# pwrseq_me17 register map
Registers are access not given, no defined reset value unless marked. A register's access mark holds for its fields unless they carry their own. Offsets are from the block's base; lines under a group give offsets from that group; [hi:lo] are bit positions; {n}, {i} and the like mark numbered series; 'fields as' and 'values as' point back to an identical list; <NAME> marks a mode.

## Memory map
0x40006800 PWRSEQ size 0x400 — Power Sequencer / Low Power Control Register.

## PWRSEQ — Power Sequencer / Low Power Control Register.
Base 0x40006800
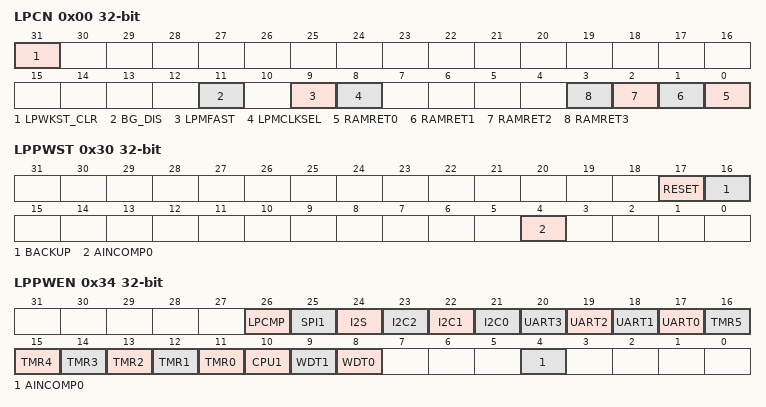
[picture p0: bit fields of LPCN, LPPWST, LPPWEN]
0x00 LPCN — Low Power Control Register.
  [31] LPWKST_CLR — Low Power Wakeup Status Register Clear
  [11] BG_DIS — Bandgap OFF. This controls the System Bandgap in DeepSleep mode.
    0=on (Bandgap is always ON.); 1=off (Bandgap is OFF in DeepSleep mode (default).)
  [9] LPMFAST — Low Power Mode Clock Select.
  [8] LPMCLKSEL — Low Power Mode APB Clock Select.
  [n] RAMRET{n} (n=0..3) — System RAM retention in BACKUP mode. These two bits are used in conjuction with RREGEN bit.
    0=dis (Disable Ram Retention.); 1=en (Enable System RAM {n} retention.)
{0x4+8i} LPWKST{i} (i=0..3) — Low Power I/O Wakeup Status Register {i}. This register indicates the low power wakeup status for GPIO{i}.
  [0] WAKEST — Wakeup IRQ flags (write ones to clear). One or more of these bits will be set when the corresponding dedicated GPIO pin (s) transition (s) from low to high or high to low. If GPIO wakeup source is selected, using PM.GPIOWKEN register, and the corresponding bit is also selected in LPWKEN register, an interrupt will be gnerated to wake up the CPU from a low power mode.
{0x8+8i} LPWKEN{i} (i=0..3) — Low Power I/O Wakeup Enable Register {i}. This register enables low power wakeup functionality for GPIO{i}.
  [30:0] WAKEEN — Enable wakeup. These bits allow wakeup from the corresponding GPIO pin (s) on transition (s) from low to high or high to low when PM.GPIOWKEN is set. Wakeup status is indicated in PPWKST register.
0x30 LPPWST — Low Power Peripheral Wakeup Status Register.
  [17] RESET — Reset Detected Wakeup Flag.
  [16] BACKUP — Backup Mode Wakeup Flag.
  [4] AINCOMP0 — Analog Input Comparator Wakeup Flag.
0x34 LPPWEN — Low Power Peripheral Wakeup Enable Register.
  [26] LPCMP — LPCMP Wakeup Enable. This bit allows wakeup from the LPCMP.
  [25] SPI1 — SPI1 Wakeup Enable. This bit allows wakeup from the SPI1.
  [24] I2S — I2S Wakeup Enable. This bit allows wakeup from the I2S.
  [23] I2C2 — I2C2 Wakeup Enable. This bit allows wakeup from the I2C2.
  [22] I2C1 — I2C1 Wakeup Enable. This bit allows wakeup from the I2C1.
  [21] I2C0 — I2C0 Wakeup Enable. This bit allows wakeup from the I2C0.
  [n+17] UART{n} (n=0..3) — UART{n} Wakeup Enable. This bit allows wakeup from the UART{n}.
  [n+11] TMR{n} (n=0..5) — TMR{n} Wakeup Enable. This bit allows wakeup from the TMR{n}.
  [10] CPU1 — CPU1 Wakeup Enable. This bit allows wakeup from the CPU1.
  [9] WDT1 — WDT1 Wakeup Enable. This bit allows wakeup from the WDT1.
  [8] WDT0 — WDT0 Wakeup Enable. This bit allows wakeup from the WDT0.
  [4] AINCOMP0 — AINCOMP0 Wakeup Enable. This bit allows wakeup from the AINCOMP0.
0x44 VBTLEPD — Low-Power VBTLE Power Down Register.
  [1] BTLE — Power Down SIMO VREGO_D.
0x48 GP0 — General Purpose Register 0
0x4C GP1 — General Purpose Register 1
